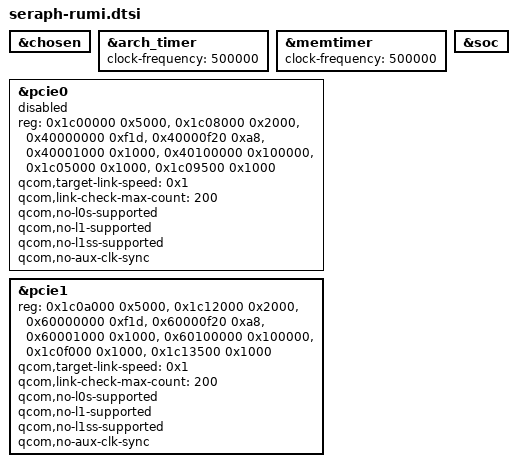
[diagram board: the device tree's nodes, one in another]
// SPDX-License-Identifier: BSD-3-Clause
/*
 * Copyright (c) Qualcomm Technologies, Inc. and/or its subsidiaries.
 */
&chosen {
};

&arch_timer {
	clock-frequency = <500000>;
};

&memtimer {
	clock-frequency = <500000>;
};

&soc {
};

&pcie0 {
	status = "disabled";
	reg = <0x1c00000 0x5000>,
		<0x1c08000 0x2000>,
		<0x40000000 0xf1d>,
		<0x40000f20 0xa8>,
		<0x40001000 0x1000>,
		<0x40100000 0x100000>,
		<0x1c05000 0x1000>,
		<0x1c09500 0x1000>;
		reg-names = "parf", "phy", "dm_core", "elbi", "iatu", "conf", "mhi",
			"rumi";
		qcom,target-link-speed = <0x1>;
		qcom,link-check-max-count = <200>; /* 1 sec */
		qcom,no-l0s-supported;
		qcom,no-l1-supported;
		qcom,no-l1ss-supported;
		qcom,no-aux-clk-sync;
};

&pcie1 {
	status = "ok";
	reg = <0x1c0a000 0x5000>,
		<0x1c12000 0x2000>,
		<0x60000000 0xf1d>,
		<0x60000f20 0xa8>,
		<0x60001000 0x1000>,
		<0x60100000 0x100000>,
		<0x1c0f000 0x1000>,
		<0x1c13500 0x1000>;
		reg-names = "parf", "phy", "dm_core", "elbi", "iatu", "conf", "mhi",
			"rumi";
		qcom,target-link-speed = <0x1>;
		qcom,link-check-max-count = <200>; /* 1 sec */
		qcom,no-l0s-supported;
		qcom,no-l1-supported;
		qcom,no-l1ss-supported;
		qcom,no-aux-clk-sync;
};
